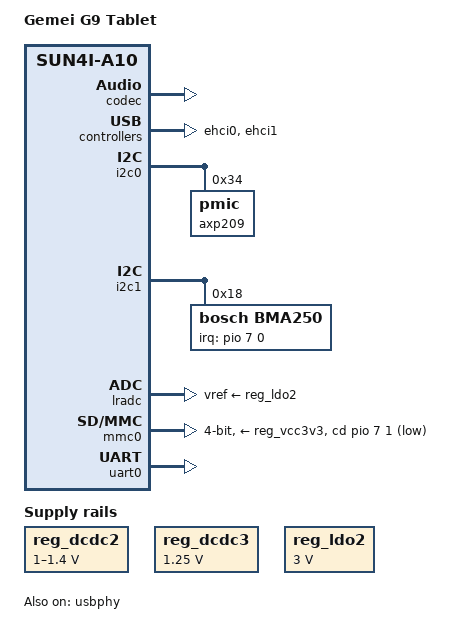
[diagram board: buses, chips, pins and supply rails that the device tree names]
/dts-v1/;
#include "sun4i-a10.dtsi"
#include "sunxi-common-regulators.dtsi"
#include <dt-bindings/gpio/gpio.h>
#include <dt-bindings/input/input.h>
#include <dt-bindings/interrupt-controller/irq.h>
/ {
	model = "Gemei G9 Tablet";
	compatible = "gemei,g9", "allwinner,sun4i-a10";
	aliases {
		serial0 = &uart0;
	};
	chosen {
		stdout-path = "serial0:115200n8";
	};
};
&codec {
	allwinner,pa-gpios = <&pio 7 15 GPIO_ACTIVE_HIGH>;
	status = "okay";
};
&cpu0 {
	cpu-supply = <&reg_dcdc2>;
};
&ehci0 {
	status = "okay";
};
&ehci1 {
	status = "okay";
};
&i2c0 {
	status = "okay";
	axp209: pmic@34 {
		reg = <0x34>;
		interrupts = <0>;
	};
};
#include "axp209.dtsi"
&i2c1 {
	status = "okay";
	bma250@18 {
		compatible = "bosch,bma250";
		reg = <0x18>;
		interrupt-parent = <&pio>;
		interrupts = <7 0 IRQ_TYPE_EDGE_RISING>;  
	};
};
&lradc {
	vref-supply = <&reg_ldo2>;
	status = "okay";
	button-158 {
		label = "Volume Down";
		linux,code = <KEY_VOLUMEDOWN>;
		channel = <0>;
		voltage = <158730>;
	};
	button-349 {
		label = "Volume Up";
		linux,code = <KEY_VOLUMEUP>;
		channel = <0>;
		voltage = <349206>;
	};
	button-1142 {
		label = "Esc";
		linux,code = <KEY_ESC>;
		channel = <0>;
		voltage = <1142856>;
	};
};
&mmc0 {
	vmmc-supply = <&reg_vcc3v3>;
	bus-width = <4>;
	cd-gpios = <&pio 7 1 GPIO_ACTIVE_LOW>;  
	status = "okay";
};
&reg_dcdc2 {
	regulator-always-on;
	regulator-min-microvolt = <1000000>;
	regulator-max-microvolt = <1400000>;
	regulator-name = "vdd-cpu";
};
&reg_dcdc3 {
	regulator-always-on;
	regulator-min-microvolt = <1250000>;
	regulator-max-microvolt = <1250000>;
	regulator-name = "vdd-int-dll";
};
&reg_ldo1 {
	regulator-name = "vdd-rtc";
};
&reg_ldo2 {
	regulator-always-on;
	regulator-min-microvolt = <3000000>;
	regulator-max-microvolt = <3000000>;
	regulator-name = "avcc";
};
&reg_usb1_vbus {
	status = "okay";
};
&reg_usb2_vbus {
	status = "okay";
};
&uart0  {
	pinctrl-names = "default";
	pinctrl-0 = <&uart0_pb_pins>;
	status = "okay";
};
&usbphy {
	usb1_vbus-supply = <&reg_usb1_vbus>;
	usb2_vbus-supply = <&reg_usb2_vbus>;
	status = "okay";
};
